VERSION "HNPBNYYYYYYYYYYYYYYYYYYYYYYYYYYYNNNNNNNNNN/4/%%%/4/'%**4NNN///"
NS_ :

BS_:

BU_: Xsens_Sensor imc_BUSFX_2_133754 Sender__XXX WC

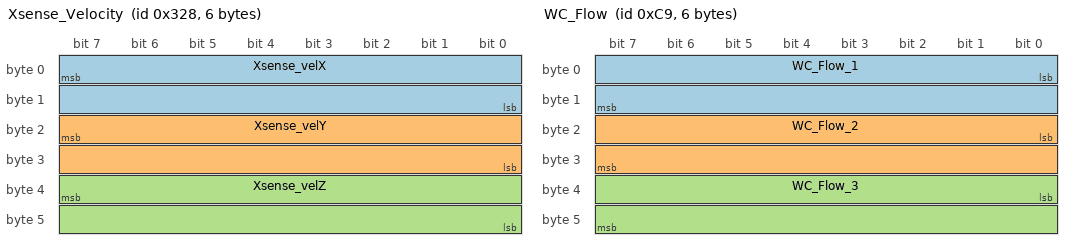
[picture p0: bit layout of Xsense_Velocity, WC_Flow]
BO_ 808 Xsense_Velocity: 6 Xsens_Sensor
 SG_ Xsense_velX : 7|16@0- (1.562500000E-2,0.000000000E+0) [-5.120000000E+2|5.119843750E+2] "m/s"  imc_BUSFX_2_133754
 SG_ Xsense_velY : 23|16@0- (1.562500000E-2,0.000000000E+0) [-5.120000000E+2|5.119843750E+2] "m/s"  imc_BUSFX_2_133754
 SG_ Xsense_velZ : 39|16@0- (1.562500000E-2,0.000000000E+0) [-5.120000000E+2|5.119843750E+2] "m/s"  imc_BUSFX_2_133754

BO_ 201 WC_Flow: 6 Sender__XXX
 SG_ WC_Flow_1 : 0|16@1+ (7.814407800E-4,0.000000000E+0) [0.000000000E+0|5.121172152E+1] "L/min"  imc_BUSFX_2_133754
 SG_ WC_Flow_2 : 16|16@1+ (1.221001220E-3,0.000000000E+0) [0.000000000E+0|8.001831495E+1] "L/min"  imc_BUSFX_2_133754
 SG_ WC_Flow_3 : 32|16@1+ (7.814407800E-4,0.000000000E+0) [0.000000000E+0|5.121172152E+1] "L/min"  imc_BUSFX_2_133754

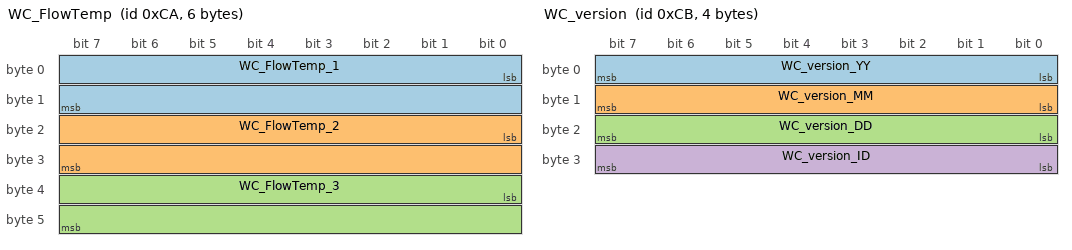
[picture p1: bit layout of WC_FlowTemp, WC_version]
BO_ 202 WC_FlowTemp: 6 Sender__XXX
 SG_ WC_FlowTemp_1 : 0|16@1+ (1.221001220E-3,0.000000000E+0) [0.000000000E+0|8.001831495E+1] "C"  imc_BUSFX_2_133754
 SG_ WC_FlowTemp_2 : 16|16@1+ (1.221001220E-3,0.000000000E+0) [0.000000000E+0|8.001831495E+1] "C"  imc_BUSFX_2_133754
 SG_ WC_FlowTemp_3 : 32|16@1+ (2.288853285E-3,0.000000000E+0) [0.000000000E+0|1.500000000E+2] "C"  imc_BUSFX_2_133754

BO_ 203 WC_version: 4 WC
 SG_ WC_version_YY : 0|8@1- (1.000000000E+0,0.000000000E+0) [-1.280000000E+2|1.270000000E+2] ""  imc_BUSFX_2_133754
 SG_ WC_version_MM : 8|8@1- (1.000000000E+0,0.000000000E+0) [-1.280000000E+2|1.270000000E+2] ""  imc_BUSFX_2_133754
 SG_ WC_version_DD : 16|8@1- (1.000000000E+0,0.000000000E+0) [-1.280000000E+2|1.270000000E+2] ""  imc_BUSFX_2_133754
 SG_ WC_version_ID : 24|8@1- (1.000000000E+0,0.000000000E+0) [-1.280000000E+2|1.270000000E+2] ""  imc_BUSFX_2_133754

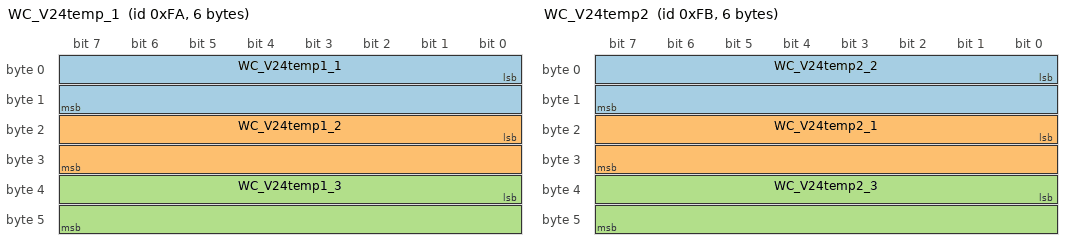
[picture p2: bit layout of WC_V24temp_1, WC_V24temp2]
BO_ 250 WC_V24temp_1: 6 Sender__XXX
 SG_ WC_V24temp1_1 : 0|16@1+ (2.288853280E-3,0.000000000E+0) [0.000000000E+0|1.499999997E+2] "C"  imc_BUSFX_2_133754
 SG_ WC_V24temp1_2 : 16|16@1+ (2.288853280E-3,0.000000000E+0) [0.000000000E+0|1.499999997E+2] "C"  imc_BUSFX_2_133754
 SG_ WC_V24temp1_3 : 32|16@1+ (2.288853280E-3,0.000000000E+0) [0.000000000E+0|1.499999997E+2] "C"  imc_BUSFX_2_133754

BO_ 251 WC_V24temp2: 6 Sender__XXX
 SG_ WC_V24temp2_2 : 0|16@1- (2.288853280E-3,0.000000000E+0) [-7.500114428E+1|7.499885543E+1] "C"  imc_BUSFX_2_133754
 SG_ WC_V24temp2_1 : 16|16@1- (2.288853280E-3,0.000000000E+0) [-7.500114428E+1|7.499885543E+1] "C"  imc_BUSFX_2_133754
 SG_ WC_V24temp2_3 : 32|16@1- (2.288853280E-3,0.000000000E+0) [-7.500114428E+1|7.499885543E+1] "C"  imc_BUSFX_2_133754

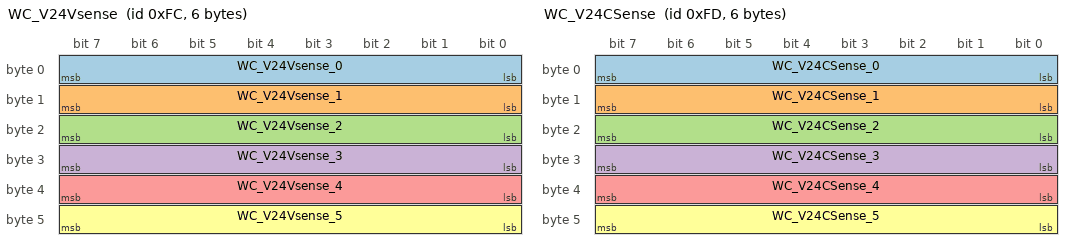
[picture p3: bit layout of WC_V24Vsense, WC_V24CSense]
BO_ 252 WC_V24Vsense: 6 Sender__XXX
 SG_ WC_V24Vsense_0 : 0|8@1+ (1.176470588E-1,0.000000000E+0) [0.000000000E+0|3.000000000E+1] "V"  imc_BUSFX_2_133754
 SG_ WC_V24Vsense_1 : 8|8@1+ (1.176470588E-1,0.000000000E+0) [0.000000000E+0|3.000000000E+1] "V"  imc_BUSFX_2_133754
 SG_ WC_V24Vsense_2 : 16|8@1+ (1.176470588E-1,0.000000000E+0) [0.000000000E+0|3.000000000E+1] "V"  imc_BUSFX_2_133754
 SG_ WC_V24Vsense_3 : 24|8@1+ (1.176470588E-1,0.000000000E+0) [0.000000000E+0|3.000000000E+1] "V"  imc_BUSFX_2_133754
 SG_ WC_V24Vsense_4 : 32|8@1+ (1.176470588E-1,0.000000000E+0) [0.000000000E+0|3.000000000E+1] "V"  imc_BUSFX_2_133754
 SG_ WC_V24Vsense_5 : 40|8@1+ (1.176470588E-1,0.000000000E+0) [0.000000000E+0|3.000000000E+1] "V"  imc_BUSFX_2_133754

BO_ 253 WC_V24CSense: 6 Sender__XXX
 SG_ WC_V24CSense_0 : 0|8@1+ (9.803921568E-2,0.000000000E+0) [0.000000000E+0|2.500000000E+1] "A"  imc_BUSFX_2_133754
 SG_ WC_V24CSense_1 : 8|8@1+ (9.803921568E-2,0.000000000E+0) [0.000000000E+0|2.500000000E+1] "A"  imc_BUSFX_2_133754
 SG_ WC_V24CSense_2 : 16|8@1+ (9.803921568E-2,0.000000000E+0) [0.000000000E+0|2.500000000E+1] "A"  imc_BUSFX_2_133754
 SG_ WC_V24CSense_3 : 24|8@1- (9.803921568E-2,0.000000000E+0) [-1.254901961E+1|1.245098039E+1] "A"  imc_BUSFX_2_133754
 SG_ WC_V24CSense_4 : 32|8@1- (9.803921568E-2,0.000000000E+0) [-1.254901961E+1|1.245098039E+1] "A"  imc_BUSFX_2_133754
 SG_ WC_V24CSense_5 : 40|8@1- (9.803921568E-2,0.000000000E+0) [-1.254901961E+1|1.245098039E+1] "A"  imc_BUSFX_2_133754

BO_ 300 EMS_Error: 7 Sender__XXX
 SG_ cell_voltage_extreme_low : 0|1@1- (1.000000000E+0,0.000000000E+0) [-1.000000000E+0|0.000000000E+0] ""  imc_BUSFX_2_133754
 SG_ cell_voltage_extreme_high : 1|1@1- (1.000000000E+0,0.000000000E+0) [-1.000000000E+0|0.000000000E+0] ""  imc_BUSFX_2_133754
 SG_ wizardcontroller_nc : 2|1@1- (1.000000000E+0,0.000000000E+0) [-1.000000000E+0|0.000000000E+0] ""  imc_BUSFX_2_133754
 SG_ steer_nc : 3|1@1- (1.000000000E+0,0.000000000E+0) [-1.000000000E+0|0.000000000E+0] ""  imc_BUSFX_2_133754
 SG_ dashboard_nc : 4|1@1- (1.000000000E+0,0.000000000E+0) [-1.000000000E+0|0.000000000E+0] ""  imc_BUSFX_2_133754
 SG_ hydrogensensor_nc : 5|1@1- (1.000000000E+0,0.000000000E+0) [-1.000000000E+0|0.000000000E+0] ""  imc_BUSFX_2_133754
 SG_ hydrogen_percentage_high : 6|1@1- (1.000000000E+0,0.000000000E+0) [-1.000000000E+0|0.000000000E+0] ""  imc_BUSFX_2_133754
 SG_ emergency_shutdown : 7|1@1- (1.000000000E+0,0.000000000E+0) [-1.000000000E+0|0.000000000E+0] ""  imc_BUSFX_2_133754
 SG_ BMS_nc6 : 8|1@1- (1.000000000E+0,0.000000000E+0) [-1.000000000E+0|0.000000000E+0] ""  imc_BUSFX_2_133754
 SG_ BMS_nc5 : 9|1@1- (1.000000000E+0,0.000000000E+0) [-1.000000000E+0|0.000000000E+0] ""  imc_BUSFX_2_133754
 SG_ BMS_nc4 : 10|1@1- (1.000000000E+0,0.000000000E+0) [-1.000000000E+0|0.000000000E+0] ""  imc_BUSFX_2_133754
 SG_ BMS_nc3 : 11|1@1- (1.000000000E+0,0.000000000E+0) [-1.000000000E+0|0.000000000E+0] ""  imc_BUSFX_2_133754
 SG_ BMS_nc2 : 12|1@1- (1.000000000E+0,0.000000000E+0) [-1.000000000E+0|0.000000000E+0] ""  imc_BUSFX_2_133754
 SG_ BMS_nc1 : 13|1@1- (1.000000000E+0,0.000000000E+0) [-1.000000000E+0|0.000000000E+0] ""  imc_BUSFX_2_133754
 SG_ BMS_nc0 : 14|1@1- (1.000000000E+0,0.000000000E+0) [-1.000000000E+0|0.000000000E+0] ""  imc_BUSFX_2_133754
 SG_ flow_port_openloop_extreme_low : 16|1@1- (1.000000000E+0,0.000000000E+0) [-1.000000000E+0|0.000000000E+0] ""  imc_BUSFX_2_133754
 SG_ flow_starboard_openloop_extreme_ : 17|1@1- (1.000000000E+0,0.000000000E+0) [-1.000000000E+0|0.000000000E+0] ""  imc_BUSFX_2_133754
 SG_ flow_dcdc_extreme_low : 18|1@1- (1.000000000E+0,0.000000000E+0) [-1.000000000E+0|0.000000000E+0] ""  imc_BUSFX_2_133754
 SG_ flow_motor_extreme_low : 19|1@1- (1.000000000E+0,0.000000000E+0) [-1.000000000E+0|0.000000000E+0] ""  imc_BUSFX_2_133754
 SG_ v24_temperature_extreme_high : 20|1@1- (1.000000000E+0,0.000000000E+0) [-1.000000000E+0|0.000000000E+0] ""  imc_BUSFX_2_133754
 SG_ motor_temp_extreme_high : 21|1@1- (1.000000000E+0,0.000000000E+0) [-1.000000000E+0|0.000000000E+0] ""  imc_BUSFX_2_133754
 SG_ cell_temperature_extreme_low : 22|1@1- (1.000000000E+0,0.000000000E+0) [-1.000000000E+0|0.000000000E+0] ""  imc_BUSFX_2_133754
 SG_ cell_temperature_extreme_high : 23|1@1- (1.000000000E+0,0.000000000E+0) [-1.000000000E+0|0.000000000E+0] ""  imc_BUSFX_2_133754
 SG_ temp_battery_loop_extreme_high : 24|1@1- (1.000000000E+0,0.000000000E+0) [-1.000000000E+0|0.000000000E+0] ""  imc_BUSFX_2_133754
 SG_ temp_port_openloop_extreme_high : 25|1@1- (1.000000000E+0,0.000000000E+0) [-1.000000000E+0|0.000000000E+0] ""  imc_BUSFX_2_133754
 SG_ temp_starboard_openloop_extreme_ : 26|1@1- (1.000000000E+0,0.000000000E+0) [-1.000000000E+0|0.000000000E+0] ""  imc_BUSFX_2_133754
 SG_ temp_dcdc_loop_extreme_high : 27|1@1- (1.000000000E+0,0.000000000E+0) [-1.000000000E+0|0.000000000E+0] ""  imc_BUSFX_2_133754
 SG_ temp_fuelcell_loop_extreme_high : 28|1@1- (1.000000000E+0,0.000000000E+0) [-1.000000000E+0|0.000000000E+0] ""  imc_BUSFX_2_133754
 SG_ temp_motor_loop_extreme_high : 29|1@1- (1.000000000E+0,0.000000000E+0) [-1.000000000E+0|0.000000000E+0] ""  imc_BUSFX_2_133754
 SG_ flow_fuel_cell_extreme_low : 30|1@1- (1.000000000E+0,0.000000000E+0) [-1.000000000E+0|0.000000000E+0] ""  imc_BUSFX_2_133754
 SG_ flow_battery_extreme_low : 31|1@1- (1.000000000E+0,0.000000000E+0) [-1.000000000E+0|0.000000000E+0] ""  imc_BUSFX_2_133754
 SG_ v24_temperature_low : 32|1@1- (1.000000000E+0,0.000000000E+0) [-1.000000000E+0|0.000000000E+0] ""  imc_BUSFX_2_133754
 SG_ v24_temperature_high : 33|1@1- (1.000000000E+0,0.000000000E+0) [-1.000000000E+0|0.000000000E+0] ""  imc_BUSFX_2_133754
 SG_ v24_voltage_low : 34|1@1- (1.000000000E+0,0.000000000E+0) [-1.000000000E+0|0.000000000E+0] ""  imc_BUSFX_2_133754
 SG_ v24_voltage_high : 35|1@1- (1.000000000E+0,0.000000000E+0) [-1.000000000E+0|0.000000000E+0] ""  imc_BUSFX_2_133754
 SG_ cell_temperature_low : 36|1@1- (1.000000000E+0,0.000000000E+0) [-1.000000000E+0|0.000000000E+0] ""  imc_BUSFX_2_133754
 SG_ cell_temperature_high : 37|1@1- (1.000000000E+0,0.000000000E+0) [-1.000000000E+0|0.000000000E+0] ""  imc_BUSFX_2_133754
 SG_ cell_voltage_low : 38|1@1- (1.000000000E+0,0.000000000E+0) [-1.000000000E+0|0.000000000E+0] ""  imc_BUSFX_2_133754
 SG_ cell_voltage_high : 39|1@1- (1.000000000E+0,0.000000000E+0) [-1.000000000E+0|0.000000000E+0] ""  imc_BUSFX_2_133754
 SG_ overcurrent : 40|1@1- (1.000000000E+0,0.000000000E+0) [-1.000000000E+0|0.000000000E+0] ""  imc_BUSFX_2_133754
 SG_ motor_temp_high : 41|1@1- (1.000000000E+0,0.000000000E+0) [-1.000000000E+0|0.000000000E+0] ""  imc_BUSFX_2_133754
 SG_ temp_battery_loop_high : 42|1@1- (1.000000000E+0,0.000000000E+0) [-1.000000000E+0|0.000000000E+0] ""  imc_BUSFX_2_133754
 SG_ temp_port_openloop_high : 43|1@1- (1.000000000E+0,0.000000000E+0) [-1.000000000E+0|0.000000000E+0] ""  imc_BUSFX_2_133754
 SG_ temp_starboard_openloop_high : 44|1@1- (1.000000000E+0,0.000000000E+0) [-1.000000000E+0|0.000000000E+0] ""  imc_BUSFX_2_133754
 SG_ temp_dcdc_loop_high : 45|1@1- (1.000000000E+0,0.000000000E+0) [-1.000000000E+0|0.000000000E+0] ""  imc_BUSFX_2_133754
 SG_ temp_fuelcell_loop_high : 46|1@1- (1.000000000E+0,0.000000000E+0) [-1.000000000E+0|0.000000000E+0] ""  imc_BUSFX_2_133754
 SG_ temp_motor_loop_high : 47|1@1- (1.000000000E+0,0.000000000E+0) [-1.000000000E+0|0.000000000E+0] ""  imc_BUSFX_2_133754
 SG_ FATAL_ERROR : 48|1@1- (1.000000000E+0,0.000000000E+0) [-1.000000000E+0|0.000000000E+0] ""  imc_BUSFX_2_133754
 SG_ charge_full : 49|1@1- (1.000000000E+0,0.000000000E+0) [-1.000000000E+0|0.000000000E+0] ""  imc_BUSFX_2_133754

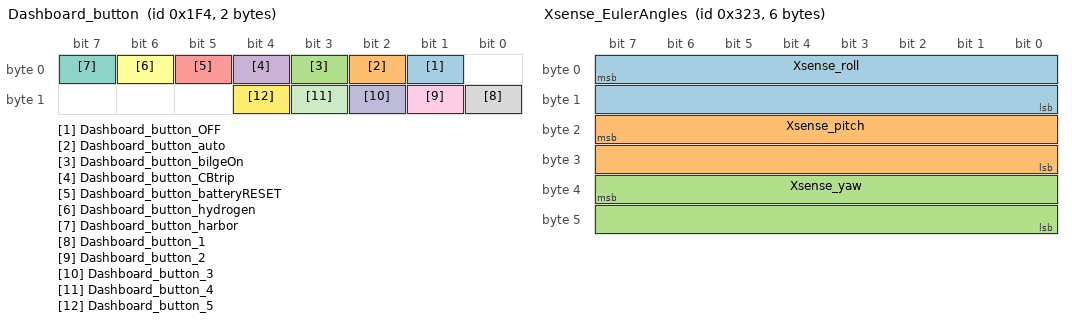
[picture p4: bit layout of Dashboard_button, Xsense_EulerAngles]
BO_ 500 Dashboard_button: 2 Sender__XXX
 SG_ Dashboard_button_OFF : 1|1@1+ (1.000000000E+0,0.000000000E+0) [0.000000000E+0|1.000000000E+0] ""  imc_BUSFX_2_133754
 SG_ Dashboard_button_auto : 2|1@1+ (1.000000000E+0,0.000000000E+0) [0.000000000E+0|1.000000000E+0] ""  imc_BUSFX_2_133754
 SG_ Dashboard_button_bilgeOn : 3|1@1+ (1.000000000E+0,0.000000000E+0) [0.000000000E+0|1.000000000E+0] ""  imc_BUSFX_2_133754
 SG_ Dashboard_button_CBtrip : 4|1@1+ (1.000000000E+0,0.000000000E+0) [0.000000000E+0|1.000000000E+0] ""  imc_BUSFX_2_133754
 SG_ Dashboard_button_batteryRESET : 5|1@1+ (1.000000000E+0,0.000000000E+0) [0.000000000E+0|1.000000000E+0] ""  imc_BUSFX_2_133754
 SG_ Dashboard_button_hydrogen : 6|1@1+ (1.000000000E+0,0.000000000E+0) [0.000000000E+0|1.000000000E+0] ""  imc_BUSFX_2_133754
 SG_ Dashboard_button_harbor : 7|1@1+ (1.000000000E+0,0.000000000E+0) [0.000000000E+0|1.000000000E+0] ""  imc_BUSFX_2_133754
 SG_ Dashboard_button_1 : 8|1@1- (1.000000000E+0,0.000000000E+0) [-1.000000000E+0|0.000000000E+0] "V"  imc_BUSFX_2_133754
 SG_ Dashboard_button_2 : 9|1@1- (1.000000000E+0,0.000000000E+0) [-1.000000000E+0|0.000000000E+0] "V"  imc_BUSFX_2_133754
 SG_ Dashboard_button_3 : 10|1@1- (1.000000000E+0,0.000000000E+0) [-1.000000000E+0|0.000000000E+0] "V"  imc_BUSFX_2_133754
 SG_ Dashboard_button_4 : 11|1@1- (1.000000000E+0,0.000000000E+0) [-1.000000000E+0|0.000000000E+0] "V"  imc_BUSFX_2_133754
 SG_ Dashboard_button_5 : 12|1@1- (1.000000000E+0,0.000000000E+0) [-1.000000000E+0|0.000000000E+0] "V"  imc_BUSFX_2_133754

BO_ 800 Xsense_SampleTime: 4 Xsens_Sensor
 SG_ Xsense_Timestamp : 7|32@0+ (1.000000000E+0,0.000000000E+0) [0.000000000E+0|4.294967295E+9] "us"  imc_BUSFX_2_133754

BO_ 801 Xsense_StatusWord: 4 Xsens_Sensor
 SG_ Xsense_FilterMode : 1|3@0+ (1.000000000E+0,0.000000000E+0) [0.000000000E+0|7.000000000E+0] ""  imc_BUSFX_2_133754
 SG_ HaveGnssTimePulse : 2|1@1+ (1,0) [0|1] ""  imc_BUSFX_2_133754
 SG_ Interpolated : 12|1@1+ (1,0) [0|1] ""  imc_BUSFX_2_133754
 SG_ SyncIn : 13|1@1+ (1,0) [0|1] ""  imc_BUSFX_2_133754
 SG_ SyncOut : 14|1@1+ (1,0) [0|1] ""  imc_BUSFX_2_133754
 SG_ Xsense_RtkStatus : 4|2@0+ (1.000000000E+0,0.000000000E+0) [0.000000000E+0|3.000000000E+0] ""  imc_BUSFX_2_133754
 SG_ ClipMagZ : 8|1@1+ (1,0) [0|1] ""  imc_BUSFX_2_133754
 SG_ Retransmitted : 10|1@1+ (1,0) [0|1] ""  imc_BUSFX_2_133754
 SG_ ClippingDetected : 11|1@1+ (1,0) [0|1] ""  imc_BUSFX_2_133754
 SG_ ClipAccX : 16|1@1+ (1,0) [0|1] ""  imc_BUSFX_2_133754
 SG_ ClipAccY : 17|1@1+ (1,0) [0|1] ""  imc_BUSFX_2_133754
 SG_ ClipAccZ : 18|1@1+ (1,0) [0|1] ""  imc_BUSFX_2_133754
 SG_ ClipGyrX : 19|1@1+ (1,0) [0|1] ""  imc_BUSFX_2_133754
 SG_ ClipGyrY : 20|1@1+ (1,0) [0|1] ""  imc_BUSFX_2_133754
 SG_ ClipGyrZ : 21|1@1+ (1,0) [0|1] ""  imc_BUSFX_2_133754
 SG_ ClipMagX : 22|1@1+ (1,0) [0|1] ""  imc_BUSFX_2_133754
 SG_ ClipMagY : 23|1@1+ (1,0) [0|1] ""  imc_BUSFX_2_133754
 SG_ SelfTestOk : 24|1@1+ (1,0) [0|1] ""  imc_BUSFX_2_133754
 SG_ OrientationValid : 25|1@1+ (1,0) [0|1] ""  imc_BUSFX_2_133754
 SG_ GpsValid : 26|1@1+ (1,0) [0|1] ""  imc_BUSFX_2_133754
 SG_ RepresentativeMotion : 29|1@1+ (1,0) [0|1] ""  imc_BUSFX_2_133754
 SG_ ExternalClockSynced : 30|1@1+ (1,0) [0|1] ""  imc_BUSFX_2_133754
 SG_ Xsense_NoRotation : 28|2@0+ (1.000000000E+0,0.000000000E+0) [0.000000000E+0|3.000000000E+0] ""  imc_BUSFX_2_133754

BO_ 802 Xsense_Error: 1 Xsens_Sensor

BO_ 803 Xsense_EulerAngles: 6 Xsens_Sensor
 SG_ Xsense_roll : 7|16@0- (7.812500000E-3,0.000000000E+0) [-2.560000000E+2|2.559921875E+2] "deg"  imc_BUSFX_2_133754
 SG_ Xsense_pitch : 23|16@0- (7.812500000E-3,0.000000000E+0) [-2.560000000E+2|2.559921875E+2] "deg"  imc_BUSFX_2_133754
 SG_ Xsense_yaw : 39|16@0- (7.812500000E-3,0.000000000E+0) [-2.560000000E+2|2.559921875E+2] "deg"  imc_BUSFX_2_133754

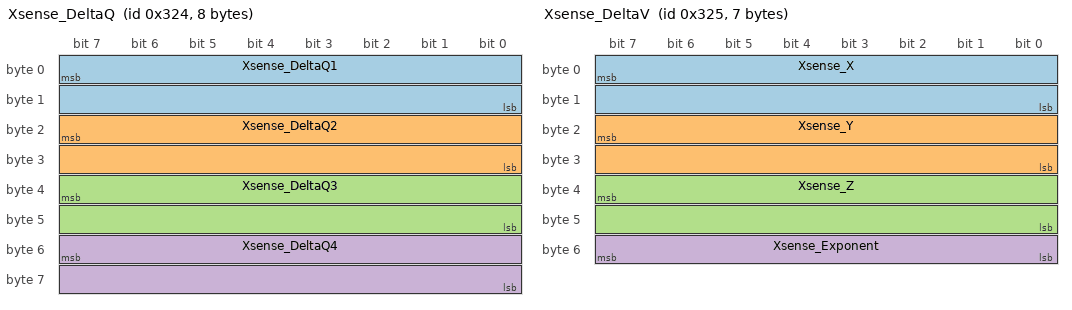
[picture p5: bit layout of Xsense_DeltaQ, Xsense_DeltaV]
BO_ 804 Xsense_DeltaQ: 8 Xsens_Sensor
 SG_ Xsense_DeltaQ1 : 7|16@0- (3.051850948E-5,0.000000000E+0) [-1.000030519E+0|1.000000000E+0] "m/s²"  imc_BUSFX_2_133754
 SG_ Xsense_DeltaQ2 : 23|16@0- (3.051850948E-5,0.000000000E+0) [-1.000030519E+0|1.000000000E+0] "m/s²"  imc_BUSFX_2_133754
 SG_ Xsense_DeltaQ3 : 39|16@0- (3.051850948E-5,0.000000000E+0) [-1.000030519E+0|1.000000000E+0] "m/s²"  imc_BUSFX_2_133754
 SG_ Xsense_DeltaQ4 : 55|16@0- (3.051850948E-5,0.000000000E+0) [-1.000030519E+0|1.000000000E+0] "m/s²"  imc_BUSFX_2_133754

BO_ 805 Xsense_DeltaV: 7 Xsens_Sensor
 SG_ Xsense_X : 7|16@0- (7.629394531E-6,0.000000000E+0) [-2.500000000E-1|2.499923706E-1] "m/s"  imc_BUSFX_2_133754
 SG_ Xsense_Y : 23|16@0- (7.629394531E-6,0.000000000E+0) [-2.500000000E-1|2.499923706E-1] "m/s"  imc_BUSFX_2_133754
 SG_ Xsense_Z : 39|16@0- (7.629394531E-6,0.000000000E+0) [-2.500000000E-1|2.499923706E-1] "m/s"  imc_BUSFX_2_133754
 SG_ Xsense_Exponent : 55|8@0+ (1.000000000E+0,0.000000000E+0) [0.000000000E+0|2.550000000E+2] ""  imc_BUSFX_2_133754

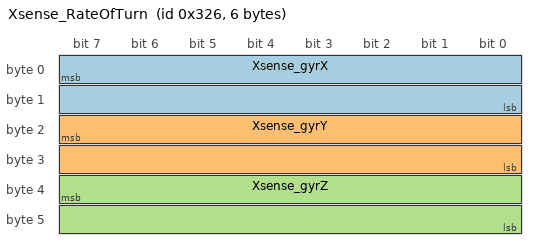
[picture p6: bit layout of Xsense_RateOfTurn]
BO_ 806 Xsense_RateOfTurn: 6 Xsens_Sensor
 SG_ Xsense_gyrX : 7|16@0- (1.953125000E-3,0.000000000E+0) [-6.400000000E+1|6.399804688E+1] "rad/s"  imc_BUSFX_2_133754
 SG_ Xsense_gyrY : 23|16@0- (1.953125000E-3,0.000000000E+0) [-6.400000000E+1|6.399804688E+1] "rad/s"  imc_BUSFX_2_133754
 SG_ Xsense_gyrZ : 39|16@0- (1.953125000E-3,0.000000000E+0) [-6.400000000E+1|6.399804688E+1] "rad/s"  imc_BUSFX_2_133754

BO_ 807 Xsense_LongLat: 8 Xsens_Sensor
 SG_ Xsense_atitude : 7|32@0- (5.960464477E-8,0.000000000E+0) [-1.280000000E+2|1.279999999E+2] "deg"  imc_BUSFX_2_133754
 SG_ Xsense_longitude : 39|32@0- (1.192092895E-7,0.000000000E+0) [-2.560000000E+2|2.559999999E+2] "deg"  imc_BUSFX_2_133754

BO_ 1313 Shunt_Current: 6 Sender__XXX
 SG_ Shunt_Current_msg : 23|32@0+ (1.000000000E-3,0.000000000E+0) [0.000000000E+0|4.294967295E+6] "A"  imc_BUSFX_2_133754

BO_ 1600 HydrogenSensor: 8 Sender__XXX
 SG_ HydrogenSensor_HydrogenLevel : 0|8@1- (2.000000000E-2,0.000000000E+0) [-2.560000000E+0|2.540000000E+0] "%"  imc_BUSFX_2_133754

CM_ "CAN-database created with: imc DEVICES 2.13 Rev. 10";
CM_ SG_ 801 Xsense_FilterMode "Mask for the 3 bit filter mode field. Values: 0 false 1 true ";
CM_ SG_ 801 HaveGnssTimePulse "Indicates that the 1PPS GNSS time pulse is present. Values: 0 false 1 true ";
CM_ SG_ 801 Interpolated "When set Indicates the sample is an interpolation between other samples. Values: 0 false 1 true ";
CM_ SG_ 801 SyncIn "When set indicates a sync-in event has been triggered. Values: 0 false 1 true ";
CM_ SG_ 801 SyncOut "When set Indicates a sync-out event has been generated. Values: 0 false 1 true ";
CM_ SG_ 801 Xsense_RtkStatus "Mask for 2 bit RTK status field. Values: 0 No RTK 1 RTK floating 2 RTK fixed ";
CM_ SG_ 801 ClipMagZ "Indicates if there was clipping on the Z-axis of the magnetometer. Values: 0 false 1 true ";
CM_ SG_ 801 Retransmitted "When set Indicates the sample was received as a retransmission. Values: 0 false 1 true ";
CM_ SG_ 801 ClippingDetected "When set Indicates clipping has occurred. Values: 0 false 1 true ";
CM_ SG_ 801 ClipAccX "Indicates if there was clipping on the X-axis of the accelerometer. Values: 0 false 1 true ";
CM_ SG_ 801 ClipAccY "Indicates if there was clipping on the Y-axis of the accelerometer. Values: 0 false 1 true ";
CM_ SG_ 801 ClipAccZ "Indicates if there was clipping on the Z-axis of the accelerometer. Values: 0 false 1 true ";
CM_ SG_ 801 ClipGyrX "Indicates if there was clipping on the X-axis of the gyroscope. Values: 0 false 1 true ";
CM_ SG_ 801 ClipGyrY "Indicates if there was clipping on the Y-axis of the gyroscope. Values: 0 false 1 true ";
CM_ SG_ 801 ClipGyrZ "Indicates if there was clipping on the Z-axis of the gyroscope. Values: 0 false 1 true ";
CM_ SG_ 801 ClipMagX "Indicates if there was clipping on the X-axis of the magnetometer. Values: 0 false 1 true ";
CM_ SG_ 801 ClipMagY "Indicates if there was clipping on the Y-axis of the magnetometer. Values: 0 false 1 true ";
CM_ SG_ 801 SelfTestOk "Set when the self test result was ok. Values: 0 false 1 true ";
CM_ SG_ 801 OrientationValid "Set when the computed orientation is valid. The orientation may be invalid during startup or when the Xsens_Sensor data is clipping during violent (for the device) motion. Values: 0 false 1 true ";
CM_ SG_ 801 GpsValid "Set when the device has a GPS receiver and the receiver says that there is a GPS position fix.. Values: 0 false 1 true ";
CM_ SG_ 801 RepresentativeMotion "Indicates if the In-Run Compass Calibration is doing the representative motion analysis. Values: 0 false 1 true ";
CM_ SG_ 801 ExternalClockSynced "Indicates whether the internal clock is synced with an external clock (Either GNNS or custom provided clock sync). Values: 0 false 1 true ";
CM_ SG_ 801 Xsense_NoRotation "Values: 1 Aborted 2 SamplesRejected 3 RunningNormally ";
CM_ BU_ imc_BUSFX_2_133754 "Serial number: 133754
Slot number: 1
Node number: 1";

BA_DEF_ BO_ "GenMsgCycleTimeus" INT 100 60000000;
BA_DEF_ SG_ "SystemSignalLongSymbol" STRING ;

BA_DEF_DEF_  "GenMsgCycleTimeus" 100000;
BA_DEF_DEF_  "SystemSignalLongSymbol" "";

BA_ "GenMsgCycleTimeus" BO_ 1313 10000;
BA_ "SystemSignalLongSymbol" SG_ 300 flow_starboard_openloop_extreme_ "flow_starboard_openloop_extreme_low";
BA_ "SystemSignalLongSymbol" SG_ 300 temp_starboard_openloop_extreme_ "temp_starboard_openloop_extreme_high";
